# PCIE0_CORE_ECC_AGGR0 register map
Vendor: Texas Instruments
Peripheral module from a debugger description file (folder am65x).
Registers are 32-bit, access not given, reset 0x0 unless marked. A register's access mark holds for its fields unless they carry their own. Offsets are as the file gives them; lines under a group give offsets from that group; [hi:lo] are bit positions; {n}, {i} and the like mark numbered series; 'fields as' and 'values as' point back to an identical list; <NAME> marks a mode.

## PCIE0_CORE_ECC_AGGR0
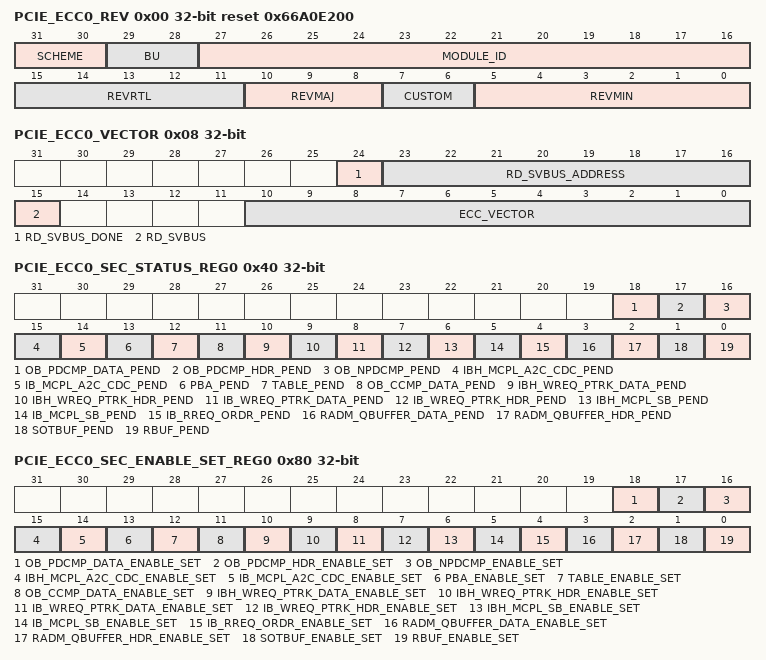
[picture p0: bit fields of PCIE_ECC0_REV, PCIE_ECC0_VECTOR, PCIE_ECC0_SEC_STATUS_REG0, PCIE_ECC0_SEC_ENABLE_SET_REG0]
0x00 PCIE_ECC0_REV ro reset 0x66A0E200 — Revision parameters
  [31:30] SCHEME
  [29:28] BU
  [27:16] MODULE_ID
  [15:11] REVRTL — RTL version
  [10:8] REVMAJ — Major version
  [7:6] CUSTOM — Custom version
  [5:0] REVMIN — Minor version
0x08 PCIE_ECC0_VECTOR — ECC Vector Register
  [24] RD_SVBUS_DONE — Status to indicate if read on serial VBUS is complete, write of any value will clear this bit. (access RW1C)
  [23:16] RD_SVBUS_ADDRESS rw — Read address
  [15] RD_SVBUS — Write 1 to trigger a read on the serial VBUS (access RW1S)
  [10:0] ECC_VECTOR rw — Value written to select the corresponding ECC RAM for control or status
0x0C PCIE_ECC0_STAT ro reset 0x13 — Misc Status
  [10:0] NUM_RAMS — Indicates the number of RAMS serviced by the ECC aggregator
0x3C PCIE_ECC0_SEC_EOI_REG — EOI Register The EOI register is used to re-trigger the pulse interrupt signal to ensure that any nested interrupt events are serviced. The software interrupt handler must write to the EOI register at the end of the current interrupt processing routine, so that new events can re-trigger the pulse interrupt signal again. For level interrupt signals the EOI register is not functional and must not be used.
  [0] EOI_WR — EOI Register (access RW1S)
0x40 PCIE_ECC0_SEC_STATUS_REG0 — Interrupt Status Register 0
  [18] OB_PDCMP_DATA_PEND — Interrupt Pending Status for ob_pdcmp_data_pend (access RW1S)
  [17] OB_PDCMP_HDR_PEND — Interrupt Pending Status for ob_pdcmp_hdr_pend (access RW1S)
  [16] OB_NPDCMP_PEND — Interrupt Pending Status for ob_npdcmp_pend (access RW1S)
  [15] IBH_MCPL_A2C_CDC_PEND — Interrupt Pending Status for ibh_mcpl_a2c_cdc_pend (access RW1S)
  [14] IB_MCPL_A2C_CDC_PEND — Interrupt Pending Status for ib_mcpl_a2c_cdc_pend (access RW1S)
  [13] PBA_PEND — Interrupt Pending Status for pba_pend (access RW1S)
  [12] TABLE_PEND — Interrupt Pending Status for table_pend (access RW1S)
  [11] OB_CCMP_DATA_PEND — Interrupt Pending Status for ob_ccmp_data_pend (access RW1S)
  [10] IBH_WREQ_PTRK_DATA_PEND — Interrupt Pending Status for ibh_wreq_ptrk_data_pend (access RW1S)
  [9] IBH_WREQ_PTRK_HDR_PEND — Interrupt Pending Status for ibh_wreq_ptrk_hdr_pend (access RW1S)
  [8] IB_WREQ_PTRK_DATA_PEND — Interrupt Pending Status for ib_wreq_ptrk_data_pend (access RW1S)
  [7] IB_WREQ_PTRK_HDR_PEND — Interrupt Pending Status for ib_wreq_ptrk_hdr_pend (access RW1S)
  [6] IBH_MCPL_SB_PEND — Interrupt Pending Status for ibh_mcpl_sb_pend (access RW1S)
  [5] IB_MCPL_SB_PEND — Interrupt Pending Status for ib_mcpl_sb_pend (access RW1S)
  [4] IB_RREQ_ORDR_PEND — Interrupt Pending Status for ib_rreq_ordr_pend (access RW1S)
  [3] RADM_QBUFFER_DATA_PEND — Interrupt Pending Status for radm_qbuffer_data_pend (access RW1S)
  [2] RADM_QBUFFER_HDR_PEND — Interrupt Pending Status for radm_qbuffer_hdr_pend (access RW1S)
  [1] SOTBUF_PEND — Interrupt Pending Status for sotbuf_pend (access RW1S)
  [0] RBUF_PEND — Interrupt Pending Status for rbuf_pend (access RW1S)
0x80 PCIE_ECC0_SEC_ENABLE_SET_REG0 — Interrupt Enable Set Register 0
  [18] OB_PDCMP_DATA_ENABLE_SET — Interrupt Enable Set Register for ob_pdcmp_data_pend (access RW1S)
  [17] OB_PDCMP_HDR_ENABLE_SET — Interrupt Enable Set Register for ob_pdcmp_hdr_pend (access RW1S)
  [16] OB_NPDCMP_ENABLE_SET — Interrupt Enable Set Register for ob_npdcmp_pend (access RW1S)
  [15] IBH_MCPL_A2C_CDC_ENABLE_SET — Interrupt Enable Set Register for ibh_mcpl_a2c_cdc_pend (access RW1S)
  [14] IB_MCPL_A2C_CDC_ENABLE_SET — Interrupt Enable Set Register for ib_mcpl_a2c_cdc_pend (access RW1S)
  [13] PBA_ENABLE_SET — Interrupt Enable Set Register for pba_pend (access RW1S)
  [12] TABLE_ENABLE_SET — Interrupt Enable Set Register for table_pend (access RW1S)
  [11] OB_CCMP_DATA_ENABLE_SET — Interrupt Enable Set Register for ob_ccmp_data_pend (access RW1S)
  [10] IBH_WREQ_PTRK_DATA_ENABLE_SET — Interrupt Enable Set Register for ibh_wreq_ptrk_data_pend (access RW1S)
  [9] IBH_WREQ_PTRK_HDR_ENABLE_SET — Interrupt Enable Set Register for ibh_wreq_ptrk_hdr_pend (access RW1S)
  [8] IB_WREQ_PTRK_DATA_ENABLE_SET — Interrupt Enable Set Register for ib_wreq_ptrk_data_pend (access RW1S)
  [7] IB_WREQ_PTRK_HDR_ENABLE_SET — Interrupt Enable Set Register for ib_wreq_ptrk_hdr_pend (access RW1S)
  [6] IBH_MCPL_SB_ENABLE_SET — Interrupt Enable Set Register for ibh_mcpl_sb_pend (access RW1S)
  [5] IB_MCPL_SB_ENABLE_SET — Interrupt Enable Set Register for ib_mcpl_sb_pend (access RW1S)
  [4] IB_RREQ_ORDR_ENABLE_SET — Interrupt Enable Set Register for ib_rreq_ordr_pend (access RW1S)
  [3] RADM_QBUFFER_DATA_ENABLE_SET — Interrupt Enable Set Register for radm_qbuffer_data_pend (access RW1S)
  [2] RADM_QBUFFER_HDR_ENABLE_SET — Interrupt Enable Set Register for radm_qbuffer_hdr_pend (access RW1S)
  [1] SOTBUF_ENABLE_SET — Interrupt Enable Set Register for sotbuf_pend (access RW1S)
  [0] RBUF_ENABLE_SET — Interrupt Enable Set Register for rbuf_pend (access RW1S)
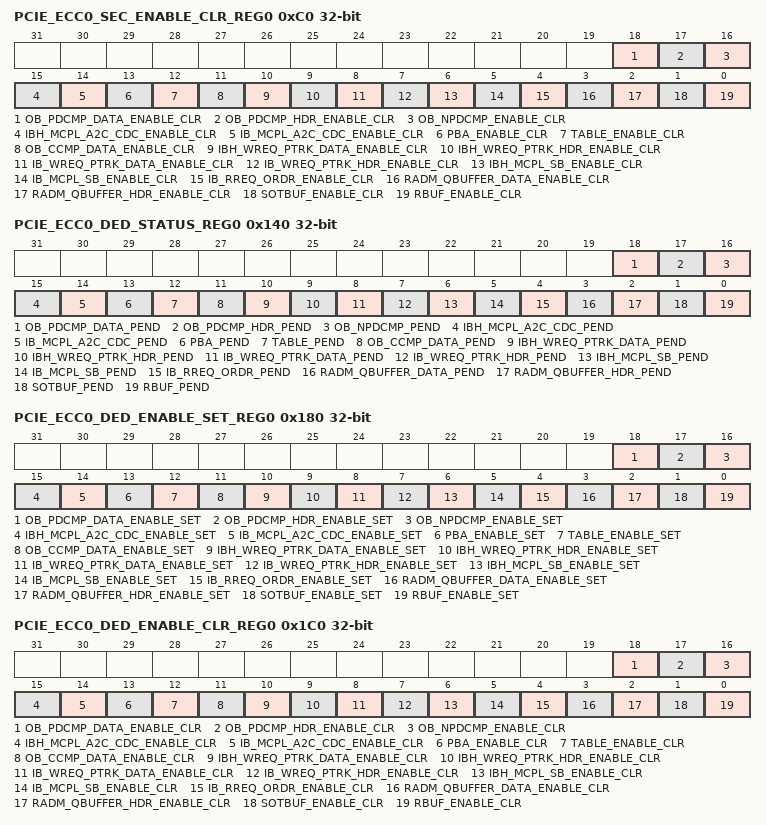
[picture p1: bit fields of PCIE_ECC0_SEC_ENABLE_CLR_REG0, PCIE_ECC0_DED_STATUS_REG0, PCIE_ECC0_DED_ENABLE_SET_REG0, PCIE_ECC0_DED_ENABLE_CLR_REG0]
0xC0 PCIE_ECC0_SEC_ENABLE_CLR_REG0 — Interrupt Enable Clear Register 0
  [18] OB_PDCMP_DATA_ENABLE_CLR — Interrupt Enable Clear Register for ob_pdcmp_data_pend (access RW1C)
  [17] OB_PDCMP_HDR_ENABLE_CLR — Interrupt Enable Clear Register for ob_pdcmp_hdr_pend (access RW1C)
  [16] OB_NPDCMP_ENABLE_CLR — Interrupt Enable Clear Register for ob_npdcmp_pend (access RW1C)
  [15] IBH_MCPL_A2C_CDC_ENABLE_CLR — Interrupt Enable Clear Register for ibh_mcpl_a2c_cdc_pend (access RW1C)
  [14] IB_MCPL_A2C_CDC_ENABLE_CLR — Interrupt Enable Clear Register for ib_mcpl_a2c_cdc_pend (access RW1C)
  [13] PBA_ENABLE_CLR — Interrupt Enable Clear Register for pba_pend (access RW1C)
  [12] TABLE_ENABLE_CLR — Interrupt Enable Clear Register for table_pend (access RW1C)
  [11] OB_CCMP_DATA_ENABLE_CLR — Interrupt Enable Clear Register for ob_ccmp_data_pend (access RW1C)
  [10] IBH_WREQ_PTRK_DATA_ENABLE_CLR — Interrupt Enable Clear Register for ibh_wreq_ptrk_data_pend (access RW1C)
  [9] IBH_WREQ_PTRK_HDR_ENABLE_CLR — Interrupt Enable Clear Register for ibh_wreq_ptrk_hdr_pend (access RW1C)
  [8] IB_WREQ_PTRK_DATA_ENABLE_CLR — Interrupt Enable Clear Register for ib_wreq_ptrk_data_pend (access RW1C)
  [7] IB_WREQ_PTRK_HDR_ENABLE_CLR — Interrupt Enable Clear Register for ib_wreq_ptrk_hdr_pend (access RW1C)
  [6] IBH_MCPL_SB_ENABLE_CLR — Interrupt Enable Clear Register for ibh_mcpl_sb_pend (access RW1C)
  [5] IB_MCPL_SB_ENABLE_CLR — Interrupt Enable Clear Register for ib_mcpl_sb_pend (access RW1C)
  [4] IB_RREQ_ORDR_ENABLE_CLR — Interrupt Enable Clear Register for ib_rreq_ordr_pend (access RW1C)
  [3] RADM_QBUFFER_DATA_ENABLE_CLR — Interrupt Enable Clear Register for radm_qbuffer_data_pend (access RW1C)
  [2] RADM_QBUFFER_HDR_ENABLE_CLR — Interrupt Enable Clear Register for radm_qbuffer_hdr_pend (access RW1C)
  [1] SOTBUF_ENABLE_CLR — Interrupt Enable Clear Register for sotbuf_pend (access RW1C)
  [0] RBUF_ENABLE_CLR — Interrupt Enable Clear Register for rbuf_pend (access RW1C)
0x13C PCIE_ECC0_DED_EOI_REG — EOI Register The EOI register is used to re-trigger the pulse interrupt signal to ensure that any nested interrupt events are serviced. The software interrupt handler must write to the EOI register at the end of the current interrupt processing routine, so that new events can re-trigger the pulse interrupt signal again. For level interrupt signals the EOI register is not functional and must not be used.
  [0] EOI_WR — EOI Register (access RW1S)
0x140 PCIE_ECC0_DED_STATUS_REG0 — Interrupt Status Register 0
  fields as PCIE_ECC0_SEC_STATUS_REG0
0x180 PCIE_ECC0_DED_ENABLE_SET_REG0 — Interrupt Enable Set Register 0
  fields as PCIE_ECC0_SEC_ENABLE_SET_REG0
0x1C0 PCIE_ECC0_DED_ENABLE_CLR_REG0 — Interrupt Enable Clear Register 0
  fields as PCIE_ECC0_SEC_ENABLE_CLR_REG0
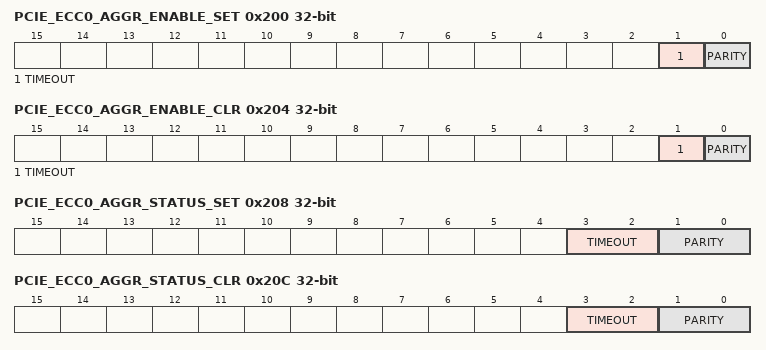
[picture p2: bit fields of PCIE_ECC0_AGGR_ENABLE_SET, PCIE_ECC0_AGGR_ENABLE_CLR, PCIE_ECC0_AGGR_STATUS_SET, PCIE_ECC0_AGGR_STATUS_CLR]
0x200 PCIE_ECC0_AGGR_ENABLE_SET — AGGR interrupt enable set Register
  [1] TIMEOUT — interrupt enable set for svbus timeout errors (access RW1S)
  [0] PARITY — interrupt enable set for parity errors (access RW1S)
0x204 PCIE_ECC0_AGGR_ENABLE_CLR — AGGR interrupt enable clear Register
  [1] TIMEOUT — interrupt enable clear for svbus timeout errors (access RW1C)
  [0] PARITY — interrupt enable clear for parity errors (access RW1C)
0x208 PCIE_ECC0_AGGR_STATUS_SET rw — AGGR interrupt status set Register
  [3:2] TIMEOUT — interrupt status set for svbus timeout errors
  [1:0] PARITY — interrupt status set for parity errors
0x20C PCIE_ECC0_AGGR_STATUS_CLR rw — AGGR interrupt status clear Register
  [3:2] TIMEOUT — interrupt status clear for svbus timeout errors
  [1:0] PARITY — interrupt status clear for parity errors
